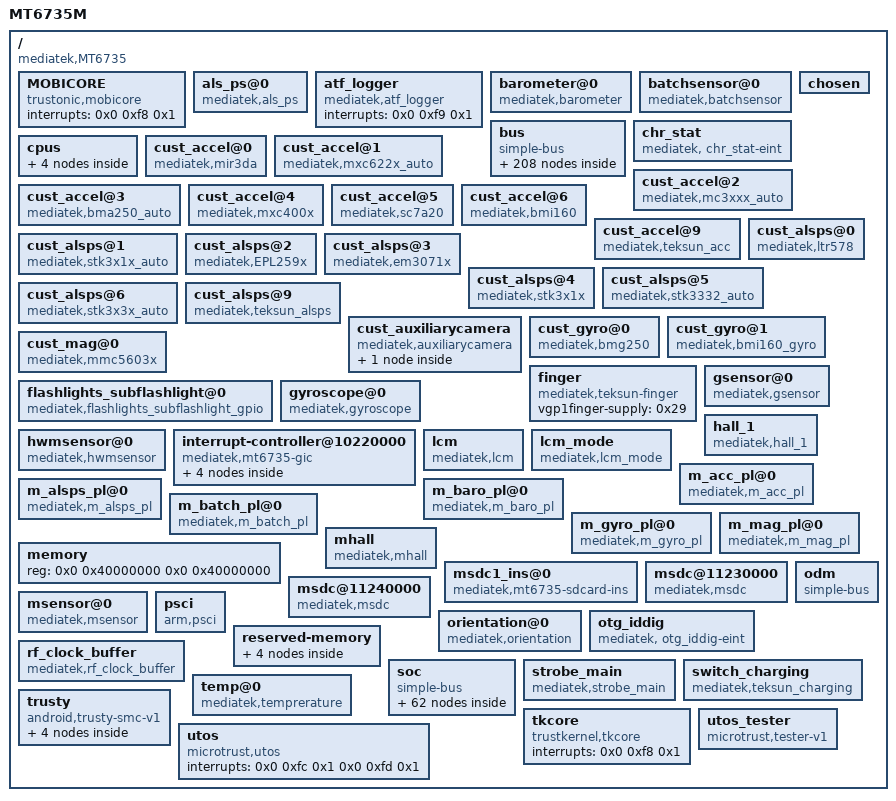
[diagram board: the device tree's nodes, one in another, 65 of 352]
/dts-v1/;

/ {
	#address-cells = <0x2>;
	#size-cells = <0x2>;
	compatible = "mediatek,MT6735";
	interrupt-parent = <0x1>;
	model = "MT6735M";

	MOBICORE {
		compatible = "trustonic,mobicore";
		interrupts = <0x0 0xf8 0x1>;
	};

	__symbols__ {
		RFIC0_01_mode = "/bus/pinctrl@0x10211000/clockbuf@1";
		RFIC0_04_mode = "/bus/pinctrl@0x10211000/clockbuf@2";
		accdet = "/bus/accdet@";
		accel = "/gsensor@0";
		als = "/soc/als";
		alsps = "/als_ps@0";
		ap_dma = "/bus/dma@11000000";
		apirtx = "/soc/irtx@11011000";
		apuart0 = "/soc/apuart0@11002000";
		apuart1 = "/soc/apuart1@11003000";
		apuart2 = "/soc/apuart2@11004000";
		apuart3 = "/soc/apuart3@11005000";
		apxgpt = "/soc/apxgpt@10004000";
		audgpio = "/bus/mt_soc_dl1_pcm@11220000";
		auxadc = "/bus/adc_hw@11001000";
		auxiliarycamera_parameter = "/cust_auxiliarycamera/auxiliarycamera_parameter";
		bat_comm = "/bus/bat_comm";
		bat_meter = "/bus/bat_meter";
		bat_notify = "/bus/bat_notify";
		bus = "/bus";
		chosen = "/chosen";
		chr_stat = "/chr_stat";
		consys = "/soc/consys@18070000";
		cpu0 = "/cpus/cpu@000";
		cpu1 = "/cpus/cpu@001";
		cpu2 = "/cpus/cpu@002";
		cpu3 = "/cpus/cpu@003";
		cpu_dbgapb = "/bus/cpu_dbgapb";
		cpus = "/cpus";
		cpuxgpt = "/soc/cpuxgpt@10200000";
		cust_accel_bma250_auto = "/cust_accel@3";
		cust_accel_bmi160 = "/cust_accel@6";
		cust_accel_mc3xxx_auto = "/cust_accel@2";
		cust_accel_mir3da = "/cust_accel@0";
		cust_accel_mxc4005xc = "/cust_accel@4";
		cust_accel_mxc622x_auto = "/cust_accel@1";
		cust_accel_sc7a20 = "/cust_accel@5";
		cust_alsps = "/cust_alsps@9";
		cust_alsps_em3071x = "/cust_alsps@3";
		cust_alsps_epl259x = "/cust_alsps@2";
		cust_alsps_ltr559 = "/cust_alsps@0";
		cust_alsps_ltr578 = "/cust_alsps@0";
		cust_alsps_stk3332_auto = "/cust_alsps@5";
		cust_alsps_stk3x1x = "/cust_alsps@4";
		cust_alsps_stk3x1x_auto = "/cust_alsps@1";
		cust_alsps_stk3x3x_auto = "/cust_alsps@6";
		cust_auxiliarycamera = "/cust_auxiliarycamera";
		cust_gyro_bmg250 = "/cust_gyro@0";
		cust_gyro_bmi160 = "/cust_gyro@1";
		cust_mag_bmm150_new = "/cust_mag@0";
		cust_mag_mmc5603x = "/cust_mag@0";
		ddrphy = "/soc/ddrphy@10213000";
		dramc = "/soc/dramc@10214000";
		dramc_nao = "/soc/dramc_nao@1020e000";
		dsi_te = "/soc/dsi_te";
		eintc = "/bus/eintc@10005000";
		ext_buck_oc = "/soc/ext_buck_oc";
		finger = "/finger";
		flashlight = "/strobe_main";
		flashlight_core = "/bus/flashlight_core";
		flashlights_lm3642 = "/bus/flashlights_lm3642";
		gic = "/interrupt-controller@10220000";
		gpio = "/soc/gpio@10211000";
		gpio_usage_mapping = "/soc/gpio";
		gse_1 = "/soc/gse_1";
		gyro = "/gyroscope@0";
		hacc = "/soc/hacc@10008000";
		hall_1 = "/hall_1";
		hwrng = "/soc/hwrng";
		i2c0 = "/bus/i2c@11007000";
		i2c1 = "/bus/i2c@11008000";
		i2c2 = "/bus/i2c@11009000";
		i2c3 = "/bus/i2c@1100f000";
		kd_camera_hw1 = "/bus/kd_camera_hw1@15008000";
		kd_camera_hw2 = "/bus/kd_camera_hw2@15008000";
		keypad = "/bus/keypad@10003000";
		lcm = "/lcm";
		lcm_mode = "/lcm_mode";
		lcm_rst = "/bus/pinctrl@0x10211000/lcm_rst_gpio_mode1@gpio146";
		lcm_rst_default = "/bus/pinctrl@0x10211000/lcmrstdefault";
		lcm_rst_gpio_high = "/bus/pinctrl@0x10211000/lcm_rst_gpio_mode2@gpio146";
		lcm_rst_gpio_low = "/bus/pinctrl@0x10211000/lcm_rst_gpio_mode3@gpio146";
		mcu_biu = "/soc/mcu_biu@10300000";
		mcucfg = "/bus/mcucfg@10200000";
		mdcldma = "/bus/mdcldma@1000A000";
		met_smi = "/bus/met_smi@14017000";
		mhall = "/mhall";
		mmsys_config = "/bus/mmsys_config@14000000";
		msdc0 = "/msdc@11230000";
		msdc1 = "/msdc@11240000";
		msdc1_ins = "/msdc1_ins@0";
		mt_pmic_vaud28_ldo_reg = "/soc/mt_pmic_regulator/ldo_regulators/ldo_vaud28";
		mt_pmic_vaux18_ldo_reg = "/soc/mt_pmic_regulator/ldo_regulators/ldo_vaux18";
		mt_pmic_vcam_af_ldo_reg = "/soc/mt_pmic_regulator/ldo_regulators/ldo_vcamaf";
		mt_pmic_vcam_io_ldo_reg = "/soc/mt_pmic_regulator/ldo_regulators/ldo_vcamio";
		mt_pmic_vcama_ldo_reg = "/soc/mt_pmic_regulator/ldo_regulators/ldo_vcama";
		mt_pmic_vcamd_ldo_reg = "/soc/mt_pmic_regulator/ldo_regulators/ldo_vcamd";
		mt_pmic_vcn18_ldo_reg = "/soc/mt_pmic_regulator/ldo_regulators/ldo_vcn18";
		mt_pmic_vcn28_ldo_reg = "/soc/mt_pmic_regulator/ldo_regulators/ldo_vcn28";
		mt_pmic_vcn33_bt_ldo_reg = "/soc/mt_pmic_regulator/ldo_regulators/ldo_vcn33_bt";
		mt_pmic_vcn33_wifi_ldo_reg = "/soc/mt_pmic_regulator/ldo_regulators/ldo_vcn33_wifi";
		mt_pmic_vcore1_buck_reg = "/soc/mt_pmic_regulator/buck_regulators/buck_vcore1";
		mt_pmic_vefuse_ldo_reg = "/soc/mt_pmic_regulator/ldo_regulators/ldo_vefuse";
		mt_pmic_vemc33_ldo_reg = "/soc/mt_pmic_regulator/ldo_regulators/ldo_vemc_3v3";
		mt_pmic_vgp1_ldo_reg = "/soc/mt_pmic_regulator/ldo_regulators/ldo_vgp1";
		mt_pmic_vibr_ldo_reg = "/soc/mt_pmic_regulator/ldo_regulators/ldo_vibr";
		mt_pmic_vio18_ldo_reg = "/soc/mt_pmic_regulator/ldo_regulators/ldo_vio18";
		mt_pmic_vio28_ldo_reg = "/soc/mt_pmic_regulator/ldo_regulators/ldo_vio28";
		mt_pmic_vlte_buck_reg = "/soc/mt_pmic_regulator/buck_regulators/buck_vlte";
		mt_pmic_vm_ldo_reg = "/soc/mt_pmic_regulator/ldo_regulators/ldo_vm";
		mt_pmic_vmc_ldo_reg = "/soc/mt_pmic_regulator/ldo_regulators/ldo_vmc";
		mt_pmic_vmch_ldo_reg = "/soc/mt_pmic_regulator/ldo_regulators/ldo_vmch";
		mt_pmic_vpa_buck_reg = "/soc/mt_pmic_regulator/buck_regulators/buck_vpa";
		mt_pmic_vproc_buck_reg = "/soc/mt_pmic_regulator/buck_regulators/buck_vproc";
		mt_pmic_vrf18_0_ldo_reg = "/soc/mt_pmic_regulator/ldo_regulators/ldo_vrf18_0";
		mt_pmic_vrf18_1_ldo_reg = "/soc/mt_pmic_regulator/ldo_regulators/ldo_vrf18_1";
		mt_pmic_vsim1_ldo_reg = "/soc/mt_pmic_regulator/ldo_regulators/ldo_vsim1";
		mt_pmic_vsim2_ldo_reg = "/soc/mt_pmic_regulator/ldo_regulators/ldo_vsim2";
		mt_pmic_vsram_ldo_reg = "/soc/mt_pmic_regulator/ldo_regulators/ldo_vsram";
		mt_pmic_vsys22_buck_reg = "/soc/mt_pmic_regulator/buck_regulators/buck_vsys22";
		mt_pmic_vtcxo_0_ldo_reg = "/soc/mt_pmic_regulator/ldo_regulators/ldo_vtcxo_0";
		mt_pmic_vtcxo_1_ldo_reg = "/soc/mt_pmic_regulator/ldo_regulators/ldo_vtcxo_1";
		mt_pmic_vtref_ldo_reg = "/soc/mt_pmic_regulator/ldo_regulators/ldo_vtref";
		mt_pmic_vusb33_ldo_reg = "/soc/mt_pmic_regulator/ldo_regulators/ldo_vusb33";
		nfc = "/bus/nfc@0";
		odm = "/odm";
		otg_iddig = "/otg_iddig";
		pio = "/bus/pinctrl@0x10211000";
		pwm = "/bus/pwm@11006000";
		reserved_memory = "/reserved-memory";
		rf_clock_buffer_ctrl = "/rf_clock_buffer";
		spi0 = "/soc/spi@1100a000";
		ssw = "/bus/simswitch@0";
		ssw_default = "/bus/pinctrl@0x10211000/ssw0default";
		ssw_hot_plug_mode1 = "/bus/pinctrl@0x10211000/ssw@1";
		ssw_hot_plug_mode2 = "/bus/pinctrl@0x10211000/ssw@2";
		ssw_sim1_md3_sim2_md1 = "/bus/pinctrl@0x10211000/ssw@4";
		ssw_two_sims_bound_to_md1 = "/bus/pinctrl@0x10211000/ssw@3";
		subflashlight = "/flashlights_subflashlight@0";
		switch_charging = "/switch_charging";
		swtp = "/soc/swtp";
		sys_cirq = "/bus/sys_cirq@10204000";
		syscfg_pctl_a = "/bus/syscfg_pctl_a@0x10211000";
		temp = "/temp@0";
		toprgu = "/soc/toprgu@10212000";
		touch = "/bus/touch@";
		usb0 = "/bus/usb20@11200000";
		usb2jtag = "/bus/usb2jtag@10000000";
		usbiddig = "/bus/usbiddig";
		vsram_default = "/bus/pinctrl@0x10211000/vsram0default";
		vsram_output_high = "/bus/pinctrl@0x10211000/vsram@2";
		vsram_output_low = "/bus/pinctrl@0x10211000/vsram@1";
	};

	als_ps@0 {
		compatible = "mediatek,als_ps";
		linux,phandle = <0x75>;
		phandle = <0x75>;
	};

	atf_logger {
		compatible = "mediatek,atf_logger";
		interrupts = <0x0 0xf9 0x1>;
	};

	barometer@0 {
		compatible = "mediatek,barometer";
	};

	batchsensor@0 {
		compatible = "mediatek,batchsensor";
	};

	bus {
		#address-cells = <0x1>;
		#size-cells = <0x1>;
		compatible = "simple-bus";
		linux,phandle = <0x55>;
		phandle = <0x55>;
		ranges = <0x0 0x0 0x0 0xffffffff>;

		APMIXED@0x10209000 {
			compatible = "mediatek,APMIXED";
			reg = <0x10209000 0x1000>;
		};

		AP_CCIF1@0x10218000 {
			compatible = "mediatek,AP_CCIF1";
			interrupts = <0x0 0x8b 0x4>;
			reg = <0x10218000 0x1000>;
		};

		AP_DMA_IRDA@0x11000100 {
			compatible = "mediatek,AP_DMA_IRDA";
			interrupts = <0x0 0x62 0x8>;
			reg = <0x11000100 0x80>;
		};

		C2KPERIPHERALS@0x38000000 {
			compatible = "mediatek,C2K PERIPHERALS";
			reg = <0x38000000 0x0>;
		};

		CA9@0x10220000 {
			compatible = "mediatek,CA9";
			reg = <0x10220000 0x8000>;
		};

		CAM@0x15004000 {
			compatible = "mediatek,CAM";
			interrupts = <0x0 0xb7 0x8>;
			reg = <0x15004000 0x1000>;
		};

		CHIPID@08000000 {
			compatible = "mediatek,CHIPID";
			reg = <0x8000000 0x4 0x8000004 0x4 0x8000008 0x4 0x800000c 0x4>;
		};

		CKSYS@0x10210000 {
			compatible = "mediatek,CKSYS";
			reg = <0x10210000 0x1000>;
		};

		DBGAPB@0x10400000 {
			compatible = "mediatek,DBGAPB";
			interrupts = <0x0 0x84 0x8>;
			reg = <0x10400000 0xc00000>;
		};

		DEBUGTOP_CA7L@0x10800000 {
			compatible = "mediatek,DEBUGTOP_CA7L";
			reg = <0x10800000 0x400000>;
		};

		DEBUGTOP_MD1@0x10450000 {
			compatible = "mediatek,DEBUGTOP_MD1";
			reg = <0x10450000 0x20000>;
		};

		DEBUGTOP_MD2@0x10470000 {
			compatible = "mediatek,DEBUGTOP_MD2";
			reg = <0x10470000 0x10000>;
		};

		DEVAPC@10207000 {
			compatible = "mediatek,DEVAPC";
			interrupts = <0x0 0x86 0x8>;
			reg = <0x10207000 0x1000>;
		};

		DEVAPC_AO@10007000 {
			compatible = "mediatek,DEVAPC_AO";
			reg = <0x10007000 0x1000>;
		};

		DISPSYS@14007000 {
			compatible = "mediatek,DISPSYS";
			interrupts = <0x0 0xc1 0x8 0x0 0x0 0x8 0x0 0xc3 0x8 0x0 0x0 0x8 0x0 0xc5 0x8 0x0 0xc6 0x8 0x0 0xc7 0x8 0x0 0xc8 0x8 0x0 0xc9 0x8 0x0 0xca 0x8 0x0 0x0 0x8 0x0 0x75 0x8 0x0 0x0 0x8 0x0 0xba 0x8 0x0 0xcc 0x8 0x0 0xcd 0x8 0x0 0xce 0x8 0x0 0xb0 0x8 0x0 0x0 0x8 0x0 0x0 0x8 0x0 0x0 0x8 0x0 0x0 0x8 0x0 0x0 0x8 0x0 0x0 0x8 0x0 0x0 0x8 0x0 0x0 0x8 0x0 0x0 0x8 0x0 0x0 0x8>;
			reg = <0x14007000 0x1000 0x0 0x0 0x14009000 0x1000 0x0 0x0 0x1400b000 0x1000 0x1400c000 0x1000 0x1400d000 0x1000 0x1400e000 0x1000 0x1400f000 0x1000 0x14010000 0x1000 0x0 0x0 0x1100e000 0x1000 0x0 0x0 0x14015000 0x1000 0x14012000 0x1000 0x14013000 0x1000 0x14000000 0x1000 0x14016000 0x1000 0x14017000 0x1000 0x14018000 0x1000 0x10206000 0x1000 0x10210000 0x1000 0x10211a70 0xc 0x10211974 0xc 0x10211b70 0xc 0x10206044 0xc 0x10206514 0xc 0x10206558 0xc 0x102100a0 0x1000 0x10209260 0x1000 0x10209264 0x1000 0x0 0x0 0x10209000 0x1000>;
		};

		DISP_AAL@0x1400E000 {
			compatible = "mediatek,DISP_AAL";
			interrupts = <0x0 0xc8 0x8>;
			reg = <0x1400e000 0x1000>;
		};

		DISP_CCORR@0x1400D000 {
			compatible = "mediatek,DISP_CCORR";
			interrupts = <0x0 0xc7 0x8>;
			reg = <0x1400d000 0x1000>;
		};

		DISP_COLOR@0x1400C000 {
			compatible = "mediatek,DISP_COLOR";
			interrupts = <0x0 0xc6 0x8>;
			reg = <0x1400c000 0x1000>;
		};

		DISP_DITHER@0x14010000 {
			compatible = "mediatek,DISP_DITHER";
			interrupts = <0x0 0xca 0x8>;
			reg = <0x14010000 0x1000>;
		};

		DISP_GAMMA@0x1400F000 {
			compatible = "mediatek,DISP_GAMMA";
			interrupts = <0x0 0xc9 0x8>;
			reg = <0x1400f000 0x1000>;
		};

		DISP_OVL0@0x14007000 {
			compatible = "mediatek,DISP_OVL0";
			interrupts = <0x0 0xc1 0x8>;
			reg = <0x14007000 0x1000>;
		};

		DISP_OVL1@0x14008000 {
			compatible = "mediatek,DISP_OVL1";
			interrupts = <0x0 0xc2 0x8>;
			reg = <0x14008000 0x1000>;
		};

		DISP_PWM0@0x1100E000 {
			compatible = "mediatek,DISP_PWM0";
			reg = <0x1100e000 0x1000>;
		};

		DISP_PWM@0x14014000 {
			compatible = "mediatek,DISP_PWM";
			reg = <0x14014000 0x1000>;
		};

		DISP_RDMA0@0x14009000 {
			compatible = "mediatek,DISP_RDMA0";
			interrupts = <0x0 0xc3 0x8>;
			reg = <0x14009000 0x1000>;
		};

		DISP_RDMA1@0x1400A000 {
			compatible = "mediatek,DISP_RDMA1";
			interrupts = <0x0 0xc4 0x8>;
			reg = <0x1400a000 0x1000>;
		};

		DISP_UFOE@0x14011000 {
			compatible = "mediatek,DISP_UFOE";
			interrupts = <0x0 0xcb 0x8>;
			reg = <0x14011000 0x1000>;
		};

		DISP_WDMA0@0x1400B000 {
			compatible = "mediatek,DISP_WDMA0";
			interrupts = <0x0 0xc5 0x8>;
			reg = <0x1400b000 0x1000>;
		};

		DNL3_XGPT64@0x1000C000 {
			compatible = "mediatek,DNL3_XGPT64";
			interrupts = <0x0 0x9f 0x8>;
			reg = <0x1000c000 0x1000>;
		};

		DPI0@0x14013000 {
			compatible = "mediatek,DPI0";
			interrupts = <0x0 0xcd 0x8>;
			reg = <0x14013000 0x1000>;
		};

		DSI0@0x14012000 {
			compatible = "mediatek,DSI0";
			interrupts = <0x0 0xcc 0x8>;
			reg = <0x14012000 0x1000>;
		};

		EFUSEC@10206000 {
			compatible = "mediatek,EFUSEC";
			reg = <0x10206000 0x1000>;
		};

		EMI@0x10203000 {
			compatible = "mediatek,EMI";
			interrupts = <0x0 0x88 0x4>;
			reg = <0x10203000 0x1000>;
		};

		FHCTL@0x10209F00 {
			compatible = "mediatek,FHCTL";
			reg = <0x10209f00 0x100>;
		};

		G3D_CONFIG@0x13000000 {
			compatible = "mediatek,G3D_CONFIG";
			reg = <0x13000000 0x1000>;
		};

		IMGSYS@0x15000000 {
			compatible = "mediatek,IMGSYS";
			reg = <0x15000000 0x1000>;
		};

		INFRACFG@0x10201000 {
			compatible = "mediatek,INFRACFG";
			reg = <0x10201000 0x1000>;
		};

		INFRACFG_AO@0x10000000 {
			compatible = "mediatek,INFRACFG_AO";
			reg = <0x10000000 0x1000>;
		};

		INFRA_MBIST@0x1020D000 {
			compatible = "mediatek,INFRA_MBIST";
			reg = <0x1020d000 0x1000>;
		};

		INFRA_MD@0x1021C000 {
			compatible = "mediatek,INFRA_MD";
			reg = <0x1021c000 0x1000>;
		};

		IRDA@0x11010000 {
			compatible = "mediatek,IRDA";
			reg = <0x11010000 0x1000>;
		};

		ISPSYS@0x15000000 {
			compatible = "mediatek,ISPSYS";
			interrupts = <0x0 0xb6 0x8 0x0 0xb7 0x8>;
			reg = <0x15004000 0x9000 0x15000000 0x10000 0x10215000 0x1000>;
		};

		ISP_PIPEM@0x15000000 {
			compatible = "mediatek,ISP_PIPEM";
		};

		ISP_SYSR@0x15000000 {
			compatible = "mediatek,ISP_SYSR";
		};

		JPGENC@0x1500A000 {
			compatible = "mediatek,JPGENC";
			interrupts = <0x0 0xb5 0x8>;
			reg = <0x1500a000 0x1000>;
		};

		MALI@0x13040000 {
			clock-frequency = <0x1ad27480>;
			compatible = "arm,malit720", "arm,mali-t72x", "arm,malit7xx", "arm,mali-midgard";
			interrupt-names = "JOB", "MMU", "GPU";
			interrupts = <0x0 0xd4 0x8 0x0 0xd3 0x8 0x0 0xd2 0x8>;
			reg = <0x13040000 0x4000>;
		};

		MCUCFG@0x10200000 {
			compatible = "mediatek,MCUCFG";
			interrupts = <0x0 0x0 0x8>;
			reg = <0x10200000 0x200>;
		};

		MCUSYS_MCUCFG@0x10200600 {
			compatible = "mediatek,MCUSYS_MCUCFG";
			reg = <0x10200600 0xa00>;
		};

		MCUSYS_MISCCFG@0x10200400 {
			compatible = "mediatek,MCUSYS_MISCCFG";
			reg = <0x10200400 0x200>;
		};

		MD2PERIPHERALS@0x30000000 {
			compatible = "mediatek,MD2 PERIPHERALS";
			reg = <0x30000000 0x0>;
		};

		MDPERIPHERALS@0x20000000 {
			compatible = "mediatek,MD PERIPHERALS";
			reg = <0x20000000 0x0>;
		};

		MD_CCIF1@0x10219000 {
			compatible = "mediatek,MD_CCIF1";
			reg = <0x10219000 0x1000>;
		};

		MFGCFG@0x13000000 {
			compatible = "mediatek,MFGCFG";
			interrupts = <0x0 0xd2 0x8>;
			reg = <0x13000000 0x1000>;
		};

		MIPI_RX_ANA_CSI0@0x10215800 {
			compatible = "mediatek,MIPI_RX_ANA_CSI0";
			reg = <0x10215800 0x400>;
		};

		MIPI_RX_ANA_CSI1@0x10215C00 {
			compatible = "mediatek,MIPI_RX_ANA_CSI1";
			reg = <0x10215c00 0x400>;
		};

		MIPI_TX_CONFIG@0x14018000 {
			compatible = "mediatek,MIPI_TX_CONFIG";
			reg = <0x14018000 0x1000>;
		};

		MM_MUTEX@0x14015000 {
			compatible = "mediatek,MM_MUTEX";
			interrupts = <0x0 0xba 0x8>;
			reg = <0x14015000 0x1000>;
		};

		NFI@0x1100D000 {
			compatible = "mediatek,NFI";
			interrupts = <0x0 0x60 0x8>;
			reg = <0x1100d000 0x1000>;
		};

		PERICFG@0x10002000 {
			compatible = "mediatek,PERICFG";
			reg = <0x10002000 0x1000>;
		};

		PWM@0x11006000 {
			compatible = "mediatek,pwm";
			interrupts = <0x0 0x4d 0x8>;
			reg = <0x11006000 0x1000>;
		};

		PWRAP@0x10001000 {
			compatible = "mediatek,PWRAP";
			interrupts = <0x0 0xa3 0x4>;
			reg = <0x10001000 0x1000>;
		};

		RSVD@0x10009000 {
			compatible = "mediatek,RSVD";
			reg = <0x10009000 0x1000>;
		};

		RSVD@0x10200200 {
			compatible = "mediatek,RSVD";
			reg = <0x10200200 0x200>;
		};

		RSVD@0x1020C000 {
			compatible = "mediatek,RSVD";
			reg = <0x1020c000 0x1000>;
		};

		SENINF_TOP@0x15008000 {
			compatible = "mediatek,SENINF_TOP";
			interrupts = <0x0 0xb6 0x8>;
			reg = <0x15008000 0x1000>;
		};

		SLEEP@0x10006000 {
			compatible = "mediatek,SLEEP";
			interrupts = <0x0 0xa5 0x8 0x0 0xa6 0x8 0x0 0xa7 0x8 0x0 0xa8 0x8>;
			reg = <0x10006000 0x1000>;
		};

		SPI1@0x1100A000 {
			cell-index = <0x0>;
			compatible = "mediatek,SPI1";
			interrupts = <0x0 0x76 0x8>;
			reg = <0x1100a000 0x1000>;
			spi-padmacro = <0x0>;
		};

		SRAMROM@0x10202000 {
			compatible = "mediatek,SRAMROM";
			reg = <0x10202000 0x1000>;
		};

		THERM_CTRL@0x1100B000 {
			compatible = "mediatek,THERM_CTRL";
			interrupts = <0x0 0x4e 0x8>;
			reg = <0x1100b000 0x1000>;
		};

		TRNG@0x1020F000 {
			compatible = "mediatek,TRNG";
			interrupts = <0x0 0x8d 0x8>;
			reg = <0x1020f000 0x1000>;
		};

		USB1@0x11260000 {
			compatible = "mediatek,USB1";
			interrupts = <0x0 0x49 0x8>;
			reg = <0x11260000 0x10000>;
		};

		VDEC@0x1500B000 {
			compatible = "mediatek,VDEC";
			reg = <0x1500b000 0x1000>;
		};

		VDEC_FULL_TOP@0x16020000 {
			compatible = "mediatek,VDEC_FULL_TOP";
			interrupts = <0x0 0xb3 0x8>;
			reg = <0x16020000 0x10000>;
		};

		VDEC_GCON@0x16000000 {
			compatible = "mediatek,VDEC_GCON";
			reg = <0x16000000 0x1000>;
		};

		VENC@0x15009000 {
			compatible = "mediatek,VENC";
			interrupts = <0x0 0xb4 0x8>;
			reg = <0x15009000 0x1000>;
		};

		WCN_AHB@0x11270000 {
			compatible = "mediatek,WCN_AHB";
			interrupts = <0x0 0xe4 0x8>;
			reg = <0x11270000 0x10000>;
		};

		accdet@ {
			compatible = "mediatek,pmic-accdet";
			linux,phandle = <0x68>;
			phandle = <0x68>;
		};

		adc_hw@11001000 {
			compatible = "mediatek,mt6735-auxadc";
			interrupts = <0x0 0x4c 0x2>;
			linux,phandle = <0x61>;
			phandle = <0x61>;
			reg = <0x11001000 0x1000>;
		};

		audio@11220000 {
			compatible = "mediatek,audio";
			interrupts = <0x0 0x90 0x8>;
			reg = <0x11220000 0x10000>;
		};

		bat_comm {
			compatible = "mediatek,battery";
			linux,phandle = <0x5a>;
			phandle = <0x5a>;
		};

		bat_meter {
			compatible = "mediatek,bat_meter";
			linux,phandle = <0x58>;
			phandle = <0x58>;
		};

		bat_notify {
			compatible = "mediatek,bat_notify";
			linux,phandle = <0x59>;
			phandle = <0x59>;
		};

		btcvsd@10000000 {
			compatible = "mediatek,audio_bt_cvsd";
			interrupts = <0x0 0xe4 0x8>;
			offset = <0x700 0x800 0xfd0 0xfd4 0xfd8>;
			reg = <0x10000000 0x1000 0x18000000 0x10000 0x18080000 0x8000>;
		};

		btif@0x1100C000 {
			#address-cells = <0x2>;
			#size-cells = <0x2>;
			compatible = "mediatek,btif";
			interrupts = <0x0 0x5a 0x8 0x0 0x6f 0x8 0x0 0x70 0x8>;
			reg = <0x1100c000 0x1000 0x11000780 0x80 0x11000800 0x80>;
		};

		bus_dbg@10208000 {
			compatible = "mediatek,bus_dbg-v1";
			interrupts = <0x0 0x89 0x8>;
			reg = <0x10208000 0x1000>;
		};

		cpu_dbgapb {
			compatible = "mediatek,hw_dbg";
			linux,phandle = <0x5f>;
			num = <0x4>;
			phandle = <0x5f>;
			reg = <0x10810000 0x1000 0x10910000 0x1000 0x10a10000 0x1000 0x10b10000 0x1000>;
		};

		cqdma@10217c00 {
			compatible = "mediatek,cqdma";
			interrupts = <0x0 0x8a 0x8>;
			nr_channel = <0x1>;
			reg = <0x10217c00 0x400>;
		};

		dbgapb_base@1011A000 {
			compatible = "mediatek,dbgapb_base";
			reg = <0x1011a000 0x100>;
		};

		dma@11000000 {
			compatible = "mediatek,ap_dma";
			interrupts = <0x0 0x61 0x8>;
			linux,phandle = <0x60>;
			phandle = <0x60>;
			reg = <0x11000000 0x1000>;
		};

		eintc@10005000 {
			#interrupt-cells = <0x2>;
			compatible = "mediatek,mt-eic";
			interrupt-controller;
			interrupts = <0x0 0x99 0x4>;
			linux,phandle = <0x1c>;
			mediatek,debtime_setting_array = <0x0 0x7d 0x1 0xfa 0x2 0x1f4 0x3 0x3e8 0x4 0x3e80 0x5 0x7d00 0x6 0xfa00 0x7 0x1f400 0x8 0x3e800 0x9 0x7d000>;
			mediatek,debtime_setting_entry = <0xa>;
			mediatek,mapping_table_entry = <0x0>;
			mediatek,max_eint_num = <0xd5>;
			phandle = <0x1c>;
			reg = <0x10005000 0x1000>;

			pmic@206 {
				compatible = "mediatek, pmic-eint";
				debounce = <0xce 0x3e8>;
				interrupt-parent = <0x1c>;
				interrupts = <0xce 0x4>;
			};
		};

		flashlight_core {
			compatible = "mediatek,flashlight_core";
			linux,phandle = <0x70>;
			phandle = <0x70>;
		};

		flashlights_lm3642 {
			compatible = "mediatek,flashlights_lm3642";
			decouple = <0x1>;
			linux,phandle = <0x71>;
			phandle = <0x71>;

			channel@1 {
				ct = <0x0>;
				part = <0x0>;
				type = <0x0>;
			};
		};

		gce@10217000 {
			apxgpt2_count = <0x10004028>;
			audio_base = <0x11220000 0x12 0xffff0000>;
			buf_underrun_event_0 = <0x30>;
			buf_underrun_event_1 = <0x31>;
			compatible = "mediatek,gce";
			conn_peri_base = <0x18000000 0x7 0xffff0000>;
			disp_aal_frame_done = <0x20>;
			disp_aal_sof = <0xd>;
			disp_ccorr_frame_done = <0x1e>;
			disp_ccorr_sof = <0xb>;
			disp_color_frame_done = <0x1f>;
			disp_color_sof = <0xc>;
			disp_dither_base = <0x14010000 0x2 0xffff0000>;
			disp_dither_frame_done = <0x22>;
			disp_dither_sof = <0xf>;
			disp_dpi0_frame_done = <0x24>;
			disp_dsi0_frame_done = <0x25>;
			disp_gamma_frame_done = <0x21>;
			disp_gamma_sof = <0xe>;
			disp_mutex_reg = <0x14015000 0x1000>;
			disp_ovl0_frame_done = <0x19>;
			disp_ovl0_sof = <0x6>;
			disp_pwm0_sof = <0x11>;
			disp_rdma0_frame_done = <0x1b>;
			disp_rdma0_sof = <0x8>;
			disp_rdma1_frame_done = <0x1c>;
			disp_rdma1_sof = <0x9>;
			disp_wdma0_frame_done = <0x1d>;
			disp_wdma0_sof = <0xa>;
			dsi0_te_event = <0x32>;
			g3d_config_base = <0x13000000 0x0 0xffff0000>;
			gcpu_base = <0x10210000 0xf 0xffff0000>;
			imgsys_base = <0x15000000 0x4 0xffff0000>;
			infra_na3_base = <0x10030000 0xb 0xffff0000>;
			infra_na4_base = <0x10040000 0xc 0xffff0000>;
			interrupts = <0x0 0x97 0x8 0x0 0x94 0x8>;
			isp_frame_done_p2_0 = <0x43>;
			isp_frame_done_p2_1 = <0x42>;
			kp_base = <0x10010000 0x9 0xffff0000>;
			mcucfg_base = <0x10200000 0xe 0xffff0000>;
			mdp_rdma0_frame_done = <0x12>;
			mdp_rdma0_sof = <0x0>;
			mdp_rsz0_frame_done = <0x13>;
			mdp_rsz0_sof = <0x1>;
			mdp_rsz1_frame_done = <0x14>;
			mdp_rsz1_sof = <0x2>;
			mdp_tdshp_frame_done = <0x15>;
			mdp_tdshp_sof = <0x3>;
			mdp_wdma_frame_done = <0x16>;
			mdp_wdma_sof = <0x4>;
			mdp_wrot_read_frame_done = <0x18>;
			mdp_wrot_sof = <0x5>;
			mdp_wrot_write_frame_done = <0x17>;
			mm_na_base = <0x14020000 0x3 0xffff0000>;
			mmsys_config_base = <0x14000000 0x1 0xffff0000>;
			msdc0_base = <0x11230000 0x13 0xffff0000>;
			msdc1_base = <0x11240000 0x14 0xffff0000>;
			msdc2_base = <0x11250000 0x15 0xffff0000>;
			msdc3_base = <0x11260000 0x16 0xffff0000>;
			pwm_sw_base = <0x1100e000 0x63 0xfffff000>;
			reg = <0x10217000 0xc00>;
			scp_base = <0x10050000 0xd 0xffff0000>;
			scp_sram_base = <0x10020000 0xa 0xffff0000>;
			seninf_cam0_fifo_full = <0x49>;
			stream_done_0 = <0x26>;
			stream_done_1 = <0x27>;
			stream_done_2 = <0x28>;
			stream_done_3 = <0x29>;
			stream_done_4 = <0x2a>;
			stream_done_5 = <0x2b>;
			stream_done_6 = <0x2c>;
			stream_done_7 = <0x2d>;
			stream_done_8 = <0x2e>;
			stream_done_9 = <0x2f>;
			topckgen_base = <0x10000000 0x8 0xffff0000>;
			usb0_base = <0x11200000 0x10 0xffff0000>;
			usb_sif_base = <0x11210000 0x11 0xffff0000>;
			vdec_gcon_base = <0x16000000 0x5 0xffff0000>;
			venc_gcon_base = <0x17000000 0x6 0xffff0000>;
		};

		gcpu@10216000 {
			compatible = "mediatek,gcpu";
			interrupts = <0x0 0x96 0x8>;
			reg = <0x10216000 0x1000>;
		};

		gpio@0x10000e00 {
			compatible = "mediatek,fpga_gpio";
			reg = <0x10000e00 0x100>;
		};

		gps {
			compatible = "mediatek,gps";
		};

		i2c@11007000 {
			cell-index = <0x0>;
			compatible = "mediatek,mt6735m-i2c";
			def_speed = <0x64>;
			interrupts = <0x0 0x54 0x8 0x0 0x63 0x8>;
			linux,phandle = <0x63>;
			phandle = <0x63>;
			reg = <0x11007000 0x1000>;
		};

		i2c@11008000 {
			cell-index = <0x1>;
			compatible = "mediatek,mt6735m-i2c";
			def_speed = <0x64>;
			interrupts = <0x0 0x55 0x8 0x0 0x64 0x8>;
			linux,phandle = <0x64>;
			phandle = <0x64>;
			reg = <0x11008000 0x1000>;
		};

		i2c@11009000 {
			cell-index = <0x2>;
			compatible = "mediatek,mt6735m-i2c";
			def_speed = <0x64>;
			interrupts = <0x0 0x56 0x8 0x0 0x65 0x8>;
			linux,phandle = <0x65>;
			phandle = <0x65>;
			reg = <0x11009000 0x1000>;
		};

		i2c@1100f000 {
			cell-index = <0x3>;
			compatible = "mediatek,mt6735m-i2c";
			def_speed = <0x64>;
			interrupts = <0x0 0x57 0x8 0x0 0x66 0x8>;
			linux,phandle = <0x66>;
			phandle = <0x66>;
			reg = <0x1100f000 0x1000>;
		};

		kd_camera_hw1@15008000 {
			compatible = "mediatek,camera_hw";
			linux,phandle = <0x6e>;
			phandle = <0x6e>;
			reg = <0x15008000 0x1000>;
			vcama-supply = <0x2a>;
			vcamaf-supply = <0x2c>;
			vcamd-supply = <0x2b>;
			vcamio-supply = <0x2d>;
		};

		kd_camera_hw2@15008000 {
			compatible = "mediatek,camera_hw2";
			linux,phandle = <0x6f>;
			phandle = <0x6f>;
			reg = <0x15008000 0x1000>;
		};

		keypad@10003000 {
			compatible = "mediatek,kp", "mediatek,mt6735-keypad", "mediatek,mt6735m-keypad";
			interrupts = <0x0 0xa4 0x2>;
			linux,phandle = <0x57>;
			phandle = <0x57>;
			reg = <0x10003000 0x1000>;
		};

		m4u@10205000 {
			cell-index = <0x0>;
			compatible = "mediatek,m4u";
			interrupts = <0x0 0x92 0x8>;
			reg = <0x10205000 0x1000>;
		};

		mcucfg@10200000 {
			compatible = "mediatek,mt6735-mcucfg";
			interrupts = <0x0 0x47 0x4>;
			linux,phandle = <0x5d>;
			phandle = <0x5d>;
			reg = <0x10200000 0x200>;
		};

		mdcldma@1000A000 {
			compatible = "mediatek,mdcldma";
			interrupts = <0x0 0x91 0x4 0x0 0x8c 0x8 0x0 0xdd 0x2>;
			linux,phandle = <0x5b>;
			mediatek,cldma_capability = <0x2>;
			mediatek,md_id = <0x0>;
			mediatek,md_smem_size = <0x10000>;
			phandle = <0x5b>;
			pinctrl-0 = <0x1d>;
			pinctrl-1 = <0x1e>;
			pinctrl-2 = <0x1f>;
			pinctrl-3 = <0x20>;
			pinctrl-4 = <0x21>;
			pinctrl-names = "default", "vsram_output_low", "vsram_output_high", "RFIC0_01_mode", "RFIC0_04_mode";
			reg = <0x1000a000 0x1000 0x1000b000 0x1000 0x1021a000 0x1000 0x1021b000 0x1000 0x1020a000 0x1000 0x1020b000 0x1000>;
		};

		mdp_rdma@14001000 {
			compatible = "mediatek,mdp_rdma";
			interrupts = <0x0 0xbb 0x8>;
			reg = <0x14001000 0x1000>;
		};

		mdp_rsz0@14002000 {
			compatible = "mediatek,mdp_rsz0";
			interrupts = <0x0 0xbc 0x8>;
			reg = <0x14002000 0x1000>;
		};

		mdp_rsz1@14003000 {
			compatible = "mediatek,mdp_rsz1";
			interrupts = <0x0 0xbd 0x8>;
			reg = <0x14003000 0x1000>;
		};

		mdp_tdshp@14006000 {
			compatible = "mediatek,mdp_tdshp";
			interrupts = <0x0 0xbe 0x8>;
			reg = <0x14006000 0x1000>;
		};

		mdp_wdma@14004000 {
			compatible = "mediatek,mdp_wdma";
			interrupts = <0x0 0xbf 0x8>;
			reg = <0x14004000 0x1000>;
		};

		mdp_wrot@14005000 {
			compatible = "mediatek,mdp_wrot";
			interrupts = <0x0 0xc0 0x8>;
			reg = <0x14005000 0x1000>;
		};

		met_smi@14017000 {
			compatible = "mediatek,met_smi";
			linux,phandle = <0x6d>;
			phandle = <0x6d>;
			reg = <0x14017000 0x1000 0x14016000 0x1000 0x16010000 0x1000 0x15001000 0x1000 0x17001000 0x1000>;
		};

		mmsys_config@14000000 {
			compatible = "mediatek,mmsys_config";
			interrupts = <0x0 0xce 0x8>;
			linux,phandle = <0x27>;
			phandle = <0x27>;
			reg = <0x14000000 0x1000>;
		};

		mt_soc_codec_dummy_name {
			compatible = "mediatek,mt_soc_codec_dummy";
		};

		mt_soc_codec_name {
			compatible = "mediatek,mt_soc_codec_63xx";
		};

		mt_soc_dai_name {
			compatible = "mediatek,mt_soc_dai_stub";
		};

		mt_soc_deep_buffer_dl_pcm {
			compatible = "mediatek,mt_soc_pcm_deep_buffer_dl";
		};

		mt_soc_dl1_awb_pcm {
			compatible = "mediatek,mt_soc_pcm_dl1_awb";
		};

		mt_soc_dl1_pcm@11220000 {
			audclk-gpio = <0x8f 0x0>;
			audmiso-gpio = <0x90 0x0>;
			audmosi-gpio = <0x91 0x0>;
			compatible = "mediatek,mt-soc-dl1-pcm";
			extspkamp-gpio = <0x75 0x0>;
			i2s1clk-gpio = <0x50 0x0>;
			i2s1dat-gpio = <0x4e 0x0>;
			i2s1mclk-gpio = <0x9 0x0>;
			i2s1ws-gpio = <0x4f 0x0>;
			interrupts = <0x0 0x90 0x8>;
			linux,phandle = <0x6c>;
			phandle = <0x6c>;
			reg = <0x11220000 0x1000>;
			vowclk-gpio = <0x94 0x0>;
		};

		mt_soc_dl2_pcm {
			compatible = "mediatek,mt_soc_pcm_dl2";
		};

		mt_soc_dummy_pcm {
			compatible = "mediatek,mt_soc_pcm_dummy";
		};

		mt_soc_fm_i2s_awb_pcm {
			compatible = "mediatek,mt_soc_pcm_fm_i2s_awb";
		};

		mt_soc_fm_i2s_pcm {
			compatible = "mediatek,mt_soc_pcm_fm_i2s";
		};

		mt_soc_fm_mrgtx_pcm {
			compatible = "mediatek,mt_soc_pcm_fmtx";
		};

		mt_soc_hdmi_pcm {
			compatible = "mediatek,mt_soc_pcm_hdmi";
		};

		mt_soc_hp_impedance_pcm {
			compatible = "mediatek,Mt_soc_pcm_hp_impedance";
		};

		mt_soc_i2s0_awb_pcm {
			compatible = "mediatek,mt_soc_pcm_i2s0_awb";
		};

		mt_soc_i2s0_pcm {
			compatible = "mediatek,mt_soc_pcm_dl1_i2s0";
		};

		mt_soc_i2s0dl1_pcm {
			compatible = "mediatek,mt_soc_pcm_dl1_i2s0Dl1";
		};

		mt_soc_mrgrx_awb_pcm {
			compatible = "mediatek,mt_soc_pcm_mrgrx_awb";
		};

		mt_soc_mrgrx_pcm {
			compatible = "mediatek,mt_soc_pcm_mrgrx";
		};

		mt_soc_offload_gdma {
			compatible = "mediatek,mt_soc_pcm_offload_gdma";
		};

		mt_soc_routing_dai_name {
			compatible = "mediatek,mt_soc_dai_routing";
		};

		mt_soc_routing_pcm {
			compatible = "mediatek,mt_soc_pcm_routing";
			i2s1clk-gpio = <0x7 0x6>;
			i2s1dat-gpio = <0x5 0x6>;
			i2s1mclk-gpio = <0x9 0x6>;
			i2s1ws-gpio = <0x6 0x6>;
		};

		mt_soc_tdmrx_pcm {
			compatible = "mediatek,mt_soc_tdm_capture";
		};

		mt_soc_ul1_pcm {
			compatible = "mediatek,mt_soc_pcm_capture";
		};

		mt_soc_ul2_pcm {
			compatible = "mediatek,mt_soc_pcm_capture2";
		};

		mt_soc_uldlloopback_pcm {
			compatible = "mediatek,mt_soc_pcm_uldlloopback";
		};

		mt_soc_voice_md1 {
			compatible = "mediatek,mt_soc_pcm_voice_md1";
		};

		mt_soc_voice_md1_bt {
			compatible = "mediatek,mt_soc_pcm_voice_md1_bt";
		};

		mt_soc_voice_md2 {
			compatible = "mediatek,mt_soc_pcm_voice_md2";
		};

		mt_soc_voice_md2_bt {
			compatible = "mediatek,mt_soc_pcm_voice_md2_bt";
		};

		mt_soc_voip_bt_in {
			compatible = "mediatek,mt_soc_pcm_bt_dai";
		};

		mt_soc_voip_bt_out {
			compatible = "mediatek,mt_soc_pcm_dl1_bt";
		};

		nfc@0 {
			compatible = "mediatek,nfc-gpio-v2";
			gpio-eint = <0x1>;
			gpio-irq = <0x2>;
			gpio-rst = <0x3>;
			gpio-ven = <0x4>;
			linux,phandle = <0x69>;
			phandle = <0x69>;
		};

		pinctrl@0x10211000 {
			#gpio-cells = <0x2>;
			compatible = "mediatek,mt6735-pinctrl";
			gpio-controller;
			linux,phandle = <0x62>;
			mediatek,pctl-regmap = <0x28>;
			phandle = <0x62>;
			pins-are-numbered;
			reg = <0x10211000 0x1000>;

			clockbuf@1 {
				linux,phandle = <0x20>;
				phandle = <0x20>;

				pins_cmd0_dat {
					pinmux = <0x6e01>;
				};

				pins_cmd1_dat {
					pinmux = <0x6f01>;
				};

				pins_cmd2_dat {
					pinmux = <0x7001>;
				};

				pins_cmd3_dat {
					pinmux = <0x7101>;
				};

				pins_cmd4_dat {
					pinmux = <0x7201>;
				};
			};

			clockbuf@2 {
				linux,phandle = <0x21>;
				phandle = <0x21>;

				pins_cmd0_dat {
					pinmux = <0x6e04>;
				};

				pins_cmd1_dat {
					pinmux = <0x6f04>;
				};

				pins_cmd2_dat {
					pinmux = <0x7004>;
				};

				pins_cmd3_dat {
					pinmux = <0x7104>;
				};

				pins_cmd4_dat {
					pinmux = <0x7204>;
				};
			};

			lcm_rst_gpio_mode1@gpio146 {
				linux,phandle = <0x2f>;
				phandle = <0x2f>;

				pins_cmd_dat {
					pins = <0x9201>;
				};
			};

			lcm_rst_gpio_mode2@gpio146 {
				linux,phandle = <0x30>;
				phandle = <0x30>;

				pins_cmd_dat {
					output-high;
					pins = <0x9200>;
					slew-rate = <0x1>;
				};
			};

			lcm_rst_gpio_mode3@gpio146 {
				linux,phandle = <0x31>;
				phandle = <0x31>;

				pins_cmd_dat {
					output-low;
					pins = <0x9200>;
					slew-rate = <0x1>;
				};
			};

			lcmrstdefault {
				linux,phandle = <0x2e>;
				phandle = <0x2e>;
			};

			ssw0default {
				linux,phandle = <0x22>;
				phandle = <0x22>;
			};

			ssw@1 {
				linux,phandle = <0x23>;
				phandle = <0x23>;

				pins_cmd0_dat {
					pinmux = <0x904>;
				};

				pins_cmd1_dat {
					pinmux = <0x904>;
				};
			};

			ssw@2 {
				linux,phandle = <0x24>;
				phandle = <0x24>;

				pins_cmd0_dat {
					pinmux = <0x904>;
				};

				pins_cmd1_dat {
					pinmux = <0x904>;
				};
			};

			ssw@3 {
				linux,phandle = <0x25>;
				phandle = <0x25>;

				pins_cmd0_dat {
					pinmux = <0xa301>;
					slew-rate = <0x1>;
				};

				pins_cmd1_dat {
					pinmux = <0xa401>;
					slew-rate = <0x1>;
				};

				pins_cmd2_dat {
					bias-pull-up = <0x0>;
					pinmux = <0xa501>;
					slew-rate = <0x0>;
				};

				pins_cmd3_dat {
					pinmux = <0xa001>;
					slew-rate = <0x1>;
				};

				pins_cmd4_dat {
					pinmux = <0xa101>;
					slew-rate = <0x1>;
				};

				pins_cmd5_dat {
					bias-pull-up = <0x0>;
					pinmux = <0xa201>;
					slew-rate = <0x0>;
				};
			};

			ssw@4 {
				linux,phandle = <0x26>;
				phandle = <0x26>;

				pins_cmd0_dat {
					pinmux = <0xa304>;
				};

				pins_cmd1_dat {
					pinmux = <0xa404>;
				};

				pins_cmd2_dat {
					pinmux = <0xa504>;
				};

				pins_cmd3_dat {
					pinmux = <0xa001>;
				};

				pins_cmd4_dat {
					pinmux = <0xa101>;
				};

				pins_cmd5_dat {
					pinmux = <0xa201>;
				};
			};

			vsram0default {
				linux,phandle = <0x1d>;
				phandle = <0x1d>;
			};

			vsram@1 {
				linux,phandle = <0x1e>;
				phandle = <0x1e>;

				pins_cmd_dat {
					output-low;
					pinmux = <0x8c00>;
					slew-rate = <0x1>;
				};
			};

			vsram@2 {
				linux,phandle = <0x1f>;
				phandle = <0x1f>;

				pins_cmd_dat {
					output-high;
					pinmux = <0x8c00>;
					slew-rate = <0x1>;
				};
			};
		};

		ptp_fsm@1100b000 {
			compatible = "mediatek,ptp_fsm_v1";
			interrupts = <0x0 0x7d 0x8>;
			reg = <0x1100b000 0x1000>;
		};

		pwm@11006000 {
			compatible = "mediatek,pwm";
			interrupts = <0x0 0x4d 0x8>;
			linux,phandle = <0x72>;
			phandle = <0x72>;
			reg = <0x11006000 0x1000>;
		};

		simswitch@0 {
			compatible = "mediatek,sim_switch";
			linux,phandle = <0x5c>;
			phandle = <0x5c>;
			pinctrl-0 = <0x22>;
			pinctrl-1 = <0x23>;
			pinctrl-2 = <0x24>;
			pinctrl-3 = <0x25>;
			pinctrl-4 = <0x26>;
			pinctrl-names = "default", "hot_plug_mode1", "hot_plug_mode2", "two_sims_bound_to_md1", "sim1_md3_sim2_md1";
		};

		smi_common@14017000 {
			compatible = "mediatek,smi_common";
			mmsys_config = <0x27>;
			nr_larbs = <0x3>;
			reg = <0x14017000 0x1000 0x14016000 0x1000 0x16010000 0x1000 0x15001000 0x1000>;
		};

		smi_larb0@14016000 {
			cell-index = <0x0>;
			compatible = "mediatek,smi_larb0", "mediatek,smi_larb";
			interrupts = <0x0 0xb0 0x8>;
			reg = <0x14016000 0x1000>;
		};

		smi_larb1@16010000 {
			cell-index = <0x1>;
			compatible = "mediatek,smi_larb1", "mediatek,smi_larb";
			interrupts = <0x0 0xb1 0x8>;
			reg = <0x16010000 0x1000>;
		};

		smi_larb2@15001000 {
			cell-index = <0x2>;
			compatible = "mediatek,smi_larb2", "mediatek,smi_larb";
			interrupts = <0x0 0xb2 0x8>;
			reg = <0x15001000 0x1000>;
		};

		sys_cirq@10204000 {
			compatible = "mediatek,sys_cirq";
			interrupts = <0x0 0xe7 0x8>;
			linux,phandle = <0x5e>;
			mediatek,cirq_num = <0x9f>;
			mediatek,spi_start_offset = <0x48>;
			phandle = <0x5e>;
			reg = <0x10204000 0x1000>;
		};

		syscfg_pctl_a@0x10211000 {
			compatible = "mediatek,mt6735-pctl-a-syscfg", "syscon";
			linux,phandle = <0x28>;
			phandle = <0x28>;
			reg = <0x10211000 0x1000>;
		};

		touch@ {
			compatible = "mediatek,touch";
			linux,phandle = <0x67>;
			phandle = <0x67>;
			vtouch-supply = <0x29>;
		};

		usb20@11200000 {
			cell-index = <0x0>;
			compatible = "mediatek,mt6735-usb20";
			dma = <0x1>;
			dma_channels = <0x8>;
			drvvbus_gpio = <0x53 0x2>;
			dyn_fifo = <0x1>;
			interrupts = <0x0 0x48 0x8>;
			linux,phandle = <0x6a>;
			mode = <0x2>;
			multipoint = <0x1>;
			num_eps = <0x10>;
			phandle = <0x6a>;
			reg = <0x11200000 0x10000 0x11210000 0x10000>;
			soft_con = <0x1>;
		};

		usb2jtag@10000000 {
			compatible = "mediatek,usb2jtag_v1";
			linux,phandle = <0x56>;
			phandle = <0x56>;
			reg = <0x10000000 0x1000 0x11210000 0x1000>;
		};

		usbiddig {
			compatible = "mediatek,usb_iddig_eint";
			linux,phandle = <0x6b>;
			phandle = <0x6b>;
		};

		wifi@180F0000 {
			compatible = "mediatek,wifi";
			interrupts = <0x0 0xe2 0x8>;
			reg = <0x180f0000 0x5c>;
		};
	};

	chosen {
		bootargs = "console=tty0 console=ttyMT3,921600n1 vmalloc=400M androidboot.hardware=mt6735 slub_max_order=0 slub_debug=OFZPU swiotlb=noforce firmware_class.path=/vendor/firmware loop.max_part=7";
		linux,phandle = <0x32>;
		phandle = <0x32>;
	};

	chr_stat {
		compatible = "mediatek, chr_stat-eint";
		linux,phandle = <0x80>;
		phandle = <0x80>;
	};

	cpus {
		#address-cells = <0x1>;
		#size-cells = <0x0>;
		linux,phandle = <0x36>;
		phandle = <0x36>;

		cpu@000 {
			clock-frequency = <0x3b9aca00>;
			compatible = "arm,cortex-a53";
			cpu-release-addr = <0x0 0x40000200>;
			device_type = "cpu";
			enable-method = "spin-table";
			linux,phandle = <0x2>;
			phandle = <0x2>;
			reg = <0x0>;
		};

		cpu@001 {
			clock-frequency = <0x3b9aca00>;
			compatible = "arm,cortex-a53";
			cpu-release-addr = <0x0 0x40000200>;
			device_type = "cpu";
			enable-method = "spin-table";
			linux,phandle = <0x3>;
			phandle = <0x3>;
			reg = <0x1>;
		};

		cpu@002 {
			clock-frequency = <0x3b9aca00>;
			compatible = "arm,cortex-a53";
			cpu-release-addr = <0x0 0x40000200>;
			device_type = "cpu";
			enable-method = "spin-table";
			linux,phandle = <0x4>;
			phandle = <0x4>;
			reg = <0x2>;
		};

		cpu@003 {
			clock-frequency = <0x3b9aca00>;
			compatible = "arm,cortex-a53";
			cpu-release-addr = <0x0 0x40000200>;
			device_type = "cpu";
			enable-method = "spin-table";
			linux,phandle = <0x5>;
			phandle = <0x5>;
			reg = <0x3>;
		};
	};

	cust_accel@0 {
		compatible = "mediatek,mir3da";
		linux,phandle = <0x83>;
		phandle = <0x83>;
	};

	cust_accel@1 {
		compatible = "mediatek,mxc622x_auto";
		linux,phandle = <0x84>;
		phandle = <0x84>;
	};

	cust_accel@2 {
		compatible = "mediatek,mc3xxx_auto";
		linux,phandle = <0x85>;
		phandle = <0x85>;
	};

	cust_accel@3 {
		compatible = "mediatek,bma250_auto";
		linux,phandle = <0x86>;
		phandle = <0x86>;
	};

	cust_accel@4 {
		compatible = "mediatek,mxc400x";
		linux,phandle = <0x87>;
		phandle = <0x87>;
	};

	cust_accel@5 {
		compatible = "mediatek,sc7a20";
		linux,phandle = <0x88>;
		phandle = <0x88>;
	};

	cust_accel@6 {
		compatible = "mediatek,bmi160";
		linux,phandle = <0x89>;
		phandle = <0x89>;
	};

	cust_accel@9 {
		compatible = "mediatek,teksun_acc";
		direction = <0x3>;
		firlen = <0x0>;
		i2c_addr = <0x18 0x0 0x0 0x0>;
		i2c_num = <0x4>;
		is_batch_supported = <0x0>;
		power_id = <0xffff>;
		power_vol = <0x0>;
	};

	cust_alsps@0 {
		compatible = "mediatek,ltr578";
		linux,phandle = <0x8a>;
		phandle = <0x8a>;
	};

	cust_alsps@1 {
		compatible = "mediatek,stk3x1x_auto";
		linux,phandle = <0x8b>;
		phandle = <0x8b>;
	};

	cust_alsps@2 {
		compatible = "mediatek,EPL259x";
		linux,phandle = <0x8c>;
		phandle = <0x8c>;
	};

	cust_alsps@3 {
		compatible = "mediatek,em3071x";
		linux,phandle = <0x8d>;
		phandle = <0x8d>;
	};

	cust_alsps@4 {
		compatible = "mediatek,stk3x1x";
		linux,phandle = <0x8e>;
		phandle = <0x8e>;
	};

	cust_alsps@5 {
		compatible = "mediatek,stk3332_auto";
		linux,phandle = <0x8f>;
		phandle = <0x8f>;
	};

	cust_alsps@6 {
		compatible = "mediatek,stk3x3x_auto";
		linux,phandle = <0x90>;
		phandle = <0x90>;
	};

	cust_alsps@9 {
		als_level = <0x5 0x9 0x24 0x3b 0x52 0x84 0xcd 0x111 0x1f4 0x34d 0x470 0x609 0x93c 0x122f 0x1b46>;
		als_value = <0xa 0x14 0x23 0x2d 0x46 0x73 0xb4 0xf0 0x15e 0x212 0x352 0x6a4 0xa28 0x1400 0x1e00 0x2800>;
		alsctrl_val = <0x39>;
		compatible = "mediatek,teksun_alsps";
		i2c_addr = <0x48 0x0 0x0 0x0>;
		i2c_num = <0x3>;
		is_batch_supported_als = <0x0>;
		is_batch_supported_ps = <0x0>;
		ledctrl_val = <0xff>;
		linux,phandle = <0x95>;
		phandle = <0x95>;
		polling_mode_als = <0x1>;
		polling_mode_ps = <0x0>;
		power_id = <0xffff>;
		power_vol = <0x0>;
		ps_threshold_high = <0x96>;
		ps_threshold_low = <0x64>;
		psctrl_val = <0x31>;
		state_val = <0x0>;
		wait_val = <0x7>;
	};

	cust_auxiliarycamera {
		compatible = "mediatek,auxiliarycamera";
		linux,phandle = <0x81>;
		phandle = <0x81>;

		auxiliarycamera_parameter {
			cam3_1_bv_value = "gc0310,68,2";
			cam3_2_bv_value = "null";
			cam3_3_bv_value = "null";
			compatible = "mediatek,auxiliarycamera_parameter";
			cumulative_cyles = <0x2>;
			diff_percent = <0x1e>;
			linux,phandle = <0x82>;
			main1_bv_value = "gc8024mipiraw,48,-50";
			main2_bv_value = "null";
			main3_bv_value = "null";
			main4_bv_value = "null";
			main5_bv_value = "null";
			phandle = <0x82>;
		};
	};

	cust_gyro@0 {
		compatible = "mediatek,bmg250";
		linux,phandle = <0x92>;
		phandle = <0x92>;
	};

	cust_gyro@1 {
		compatible = "mediatek,bmi160_gyro";
		linux,phandle = <0x93>;
		phandle = <0x93>;
	};

	cust_mag@0 {
		compatible = "mediatek,mmc5603x";
		linux,phandle = <0x91>;
		phandle = <0x91>;
	};

	finger {
		compatible = "mediatek,teksun-finger";
		linux,phandle = <0x79>;
		phandle = <0x79>;
		vgp1finger-supply = <0x29>;
	};

	flashlights_subflashlight@0 {
		compatible = "mediatek,flashlights_subflashlight_gpio";
		linux,phandle = <0x7b>;
		phandle = <0x7b>;
	};

	gsensor@0 {
		compatible = "mediatek,gsensor";
		linux,phandle = <0x74>;
		phandle = <0x74>;
	};

	gyroscope@0 {
		compatible = "mediatek,gyroscope";
		linux,phandle = <0x76>;
		phandle = <0x76>;
	};

	hall_1 {
		compatible = "mediatek,hall_1";
		linux,phandle = <0x7e>;
		phandle = <0x7e>;
	};

	hwmsensor@0 {
		compatible = "mediatek,hwmsensor";
	};

	interrupt-controller@10220000 {
		#address-cells = <0x0>;
		#interrupt-cells = <0x3>;
		compatible = "mediatek,mt6735-gic";
		interrupt-controller;
		linux,phandle = <0x1>;
		mediatek,wdt_irq = <0xa0>;
		phandle = <0x1>;
		reg = <0x0 0x10221000 0x0 0x1000 0x0 0x10222000 0x0 0x1000 0x0 0x10200620 0x0 0x1000>;

		gic-cpuif@0 {
			compatible = "arm,gic-cpuif";
			cpu = <0x2>;
			cpuif-id = <0x0>;
		};

		gic-cpuif@1 {
			compatible = "arm,gic-cpuif";
			cpu = <0x3>;
			cpuif-id = <0x1>;
		};

		gic-cpuif@2 {
			compatible = "arm,gic-cpuif";
			cpu = <0x4>;
			cpuif-id = <0x2>;
		};

		gic-cpuif@3 {
			compatible = "arm,gic-cpuif";
			cpu = <0x5>;
			cpuif-id = <0x3>;
		};
	};

	lcm {
		compatible = "mediatek,lcm";
		linux,phandle = <0x73>;
		phandle = <0x73>;
	};

	lcm_mode {
		compatible = "mediatek,lcm_mode";
		linux,phandle = <0x7c>;
		phandle = <0x7c>;
		pinctrl-0 = <0x2e>;
		pinctrl-1 = <0x2f>;
		pinctrl-2 = <0x30>;
		pinctrl-3 = <0x31>;
		pinctrl-names = "default", "lcm_rst", "lcm_rst_gpio_high", "lcm_rst_gpio_low";
	};

	m_acc_pl@0 {
		compatible = "mediatek,m_acc_pl";
	};

	m_alsps_pl@0 {
		compatible = "mediatek,m_alsps_pl";
	};

	m_baro_pl@0 {
		compatible = "mediatek,m_baro_pl";
	};

	m_batch_pl@0 {
		compatible = "mediatek,m_batch_pl";
	};

	m_gyro_pl@0 {
		compatible = "mediatek,m_gyro_pl";
	};

	m_mag_pl@0 {
		compatible = "mediatek,m_mag_pl";
	};

	memory {
		device_type = "memory";
		reg = <0x0 0x40000000 0x0 0x40000000>;
	};

	mhall {
		compatible = "mediatek,mhall";
		linux,phandle = <0x7d>;
		phandle = <0x7d>;
	};

	msdc1_ins@0 {
		compatible = "mediatek,mt6735-sdcard-ins";
		linux,phandle = <0x35>;
		phandle = <0x35>;
	};

	msdc@11230000 {
		compatible = "mediatek,msdc";
		interrupts = <0x0 0x4f 0x8>;
		linux,phandle = <0x33>;
		phandle = <0x33>;
		reg = <0x0 0x11230000 0x0 0x10000>;
	};

	msdc@11240000 {
		compatible = "mediatek,msdc";
		interrupts = <0x0 0x50 0x8>;
		linux,phandle = <0x34>;
		phandle = <0x34>;
		reg = <0x0 0x11240000 0x0 0x10000>;
	};

	msensor@0 {
		compatible = "mediatek,msensor";
	};

	odm {
		compatible = "simple-bus";
		linux,phandle = <0x78>;
		phandle = <0x78>;
	};

	orientation@0 {
		compatible = "mediatek,orientation";
	};

	otg_iddig {
		compatible = "mediatek, otg_iddig-eint";
		linux,phandle = <0x7f>;
		phandle = <0x7f>;
	};

	psci {
		affinity_info = <0x84000004>;
		compatible = "arm,psci";
		cpu_off = <0x84000002>;
		cpu_on = <0x84000003>;
		cpu_suspend = <0x84000001>;
		method = "smc";
	};

	reserved-memory {
		#address-cells = <0x2>;
		#size-cells = <0x2>;
		linux,phandle = <0x37>;
		phandle = <0x37>;
		ranges;

		atf-reserved-memory@43000000 {
			compatible = "mediatek,mt6735-atf-reserved-memory", "mediatek,mt6735m-atf-reserved-memory", "mediatek,mt6753-atf-reserved-memory";
			no-map;
			reg = <0x0 0x43000000 0x0 0x30000>;
		};

		consys-reserve-memory {
			alignment = <0x0 0x200000>;
			compatible = "mediatek,consys-reserve-memory";
			no-map;
			size = <0x0 0x100000>;
		};

		reserve-memory-ccci_md1 {
			alignment = <0x0 0x2000000>;
			alloc-ranges = <0x0 0x40000000 0x0 0xc0000000>;
			compatible = "mediatek,reserve-memory-ccci_md1";
			no-map;
			size = <0x0 0x3810000>;
		};

		spm-reserve-memory {
			alignment = <0x0 0x10000>;
			alloc-ranges = <0x0 0x40000000 0x0 0x60000000>;
			compatible = "mediatek,spm-reserve-memory";
			no-map;
			size = <0x0 0x10000>;
		};
	};

	rf_clock_buffer {
		compatible = "mediatek,rf_clock_buffer";
		linux,phandle = <0x77>;
		mediatek,clkbuf-config = <0x2 0x2 0x2 0x2>;
		mediatek,clkbuf-quantity = <0x4>;
		phandle = <0x77>;
	};

	soc {
		#address-cells = <0x1>;
		#size-cells = <0x1>;
		compatible = "simple-bus";
		ranges = <0x0 0x0 0x0 0xffffffff>;

		als {
			compatible = "mediatek, als-eint";
			linux,phandle = <0x4f>;
			phandle = <0x4f>;
		};

		apuart0@11002000 {
			cell-index = <0x0>;
			compatible = "mediatek,mt6735-uart";
			interrupts = <0x0 0x5b 0x8 0x0 0x67 0x8 0x0 0x68 0x8>;
			linux,phandle = <0x48>;
			phandle = <0x48>;
			reg = <0x11002000 0x1000 0x11000380 0x1000 0x11000400 0x80>;
			skip_pinmux_clk = <0x1>;
		};

		apuart1@11003000 {
			cell-index = <0x1>;
			compatible = "mediatek,mt6735-uart";
			interrupts = <0x0 0x5c 0x8 0x0 0x69 0x8 0x0 0x6a 0x8>;
			linux,phandle = <0x49>;
			phandle = <0x49>;
			reg = <0x11003000 0x1000 0x11000480 0x80 0x11000500 0x80>;
			skip_pinmux_clk = <0x1>;
		};

		apuart2@11004000 {
			cell-index = <0x2>;
			compatible = "mediatek,mt6735-uart";
			interrupts = <0x0 0x5d 0x8 0x0 0x6b 0x8 0x0 0x6c 0x8>;
			linux,phandle = <0x4a>;
			phandle = <0x4a>;
			reg = <0x11004000 0x1000 0x11000580 0x80 0x11000600 0x80>;
			skip_pinmux_clk = <0x1>;
		};

		apuart3@11005000 {
			cell-index = <0x3>;
			compatible = "mediatek,mt6735-uart";
			interrupts = <0x0 0x5e 0x8 0x0 0x6d 0x8 0x0 0x6e 0x8>;
			linux,phandle = <0x4b>;
			phandle = <0x4b>;
			reg = <0x11005000 0x1000 0x11000680 0x80 0x11000700 0x80>;
			skip_pinmux_clk = <0x1>;
		};

		apxgpt@10004000 {
			clock-frequency = <0xc65d40>;
			compatible = "mediatek,APXGPT";
			interrupts = <0x0 0x98 0x8>;
			linux,phandle = <0x39>;
			phandle = <0x39>;
			reg = <0x10004000 0x1000>;
		};

		consys@18070000 {
			compatible = "mediatek,mt6735m-consys", "mediatek,mt6735-consys";
			interrupts = <0x0 0xe3 0x8 0x0 0xe1 0x8>;
			linux,phandle = <0x4d>;
			phandle = <0x4d>;
			reg = <0x18070000 0x200 0x10212000 0x100 0x10000000 0x2000 0x10006000 0x1000>;
			vcn18-supply = <0x18>;
			vcn28-supply = <0x19>;
			vcn33_bt-supply = <0x1a>;
			vcn33_wifi-supply = <0x1b>;
		};

		cpuxgpt@10200000 {
			compatible = "mediatek,mt6735-cpuxgpt";
			interrupts = <0x0 0x40 0x4 0x0 0x41 0x4 0x0 0x42 0x4 0x0 0x43 0x4 0x0 0x44 0x4 0x0 0x45 0x4 0x0 0x46 0x4 0x0 0x47 0x4>;
			linux,phandle = <0x38>;
			phandle = <0x38>;
			reg = <0x10200000 0x1000>;
		};

		ddrphy@10213000 {
			compatible = "mediatek,mt6735-ddrphy";
			linux,phandle = <0x45>;
			phandle = <0x45>;
			reg = <0x10213000 0x1000>;
		};

		dramc@10214000 {
			clock-names = "infra-cqdma";
			compatible = "mediatek,mt6735-dramc";
			linux,phandle = <0x46>;
			phandle = <0x46>;
			reg = <0x10214000 0x1000>;
		};

		dramc_nao@1020e000 {
			compatible = "mediatek,mt6735-dramc_nao";
			linux,phandle = <0x44>;
			phandle = <0x44>;
			reg = <0x1020e000 0x1000>;
		};

		dsi_te {
			compatible = "mediatek, DSI_TE_1-eint";
			linux,phandle = <0x53>;
			phandle = <0x53>;
			status = "disabled";
		};

		ext_buck_oc {
			compatible = "mediatek, ext_buck_oc-eint";
			linux,phandle = <0x51>;
			phandle = <0x51>;
			status = "disabled";
		};

		gpio {
			compatible = "mediatek,gpio_usage_mapping";
			linux,phandle = <0x42>;
			phandle = <0x42>;
		};

		gpio@10211000 {
			compatible = "mediatek,gpio";
			linux,phandle = <0x43>;
			phandle = <0x43>;
			reg = <0x10211000 0x1000>;
		};

		gse_1 {
			compatible = "mediatek, gse_1-eint";
			linux,phandle = <0x50>;
			phandle = <0x50>;
			status = "disabled";
		};

		hacc@10008000 {
			compatible = "mediatek,hacc";
			interrupts = <0x0 0xae 0x8>;
			linux,phandle = <0x4e>;
			phandle = <0x4e>;
			reg = <0x10008000 0x1000>;
		};

		hwrng {
			compatible = "mediatek,mt67xx-rng";
			linux,phandle = <0x54>;
			phandle = <0x54>;
		};

		irtx@11011000 {
			compatible = "mediatek,irtx";
			interrupts = <0x0 0x7c 0x4>;
			linux,phandle = <0x47>;
			phandle = <0x47>;
			pwm_ch = <0x0>;
			reg = <0x11011000 0x1000>;
		};

		mcu_biu@10300000 {
			compatible = "mediatek,mt6735-mcu_biu";
			linux,phandle = <0x41>;
			phandle = <0x41>;
			reg = <0x10300000 0x8000>;
		};

		mt_pmic_regulator {
			compatible = "mediatek,mt_pmic";

			buck_regulators {
				compatible = "mediatek,mt_pmic_buck_regulators";

				buck_vcore1 {
					linux,phandle = <0x3c>;
					phandle = <0x3c>;
					regulator-always-on;
					regulator-boot-on;
					regulator-enable-ramp-delay = <0xb4>;
					regulator-max-microvolt = <0x154456>;
					regulator-min-microvolt = <0x927c0>;
					regulator-name = "vcore1";
					regulator-ramp-delay = <0x186a>;
				};

				buck_vlte {
					linux,phandle = <0x3e>;
					phandle = <0x3e>;
					regulator-always-on;
					regulator-boot-on;
					regulator-enable-ramp-delay = <0xb4>;
					regulator-max-microvolt = <0x154456>;
					regulator-min-microvolt = <0x927c0>;
					regulator-name = "vlte";
					regulator-ramp-delay = <0x186a>;
				};

				buck_vpa {
					linux,phandle = <0x3a>;
					phandle = <0x3a>;
					regulator-enable-ramp-delay = <0xb4>;
					regulator-max-microvolt = <0x37b1d0>;
					regulator-min-microvolt = <0x7a120>;
					regulator-name = "vpa";
					regulator-ramp-delay = <0xc350>;
				};

				buck_vproc {
					linux,phandle = <0x3b>;
					phandle = <0x3b>;
					regulator-always-on;
					regulator-boot-on;
					regulator-enable-ramp-delay = <0xb4>;
					regulator-max-microvolt = <0x154456>;
					regulator-min-microvolt = <0x927c0>;
					regulator-name = "vproc";
					regulator-ramp-delay = <0x186a>;
				};

				buck_vsys22 {
					linux,phandle = <0x3d>;
					phandle = <0x3d>;
					regulator-always-on;
					regulator-boot-on;
					regulator-enable-ramp-delay = <0xb4>;
					regulator-max-microvolt = <0x1e6c16>;
					regulator-min-microvolt = <0x124f80>;
					regulator-name = "vsys22";
					regulator-ramp-delay = <0x186a>;
				};
			};

			ldo_regulators {
				compatible = "mediatek,mt_pmic_ldo_regulators";

				ldo_vaud28 {
					linux,phandle = <0x9>;
					phandle = <0x9>;
					regulator-boot-on;
					regulator-enable-ramp-delay = <0x108>;
					regulator-max-microvolt = <0x2ab980>;
					regulator-min-microvolt = <0x2ab980>;
					regulator-name = "vaud28";
				};

				ldo_vaux18 {
					linux,phandle = <0x6>;
					phandle = <0x6>;
					regulator-boot-on;
					regulator-enable-ramp-delay = <0x108>;
					regulator-max-microvolt = <0x1b7740>;
					regulator-min-microvolt = <0x1b7740>;
					regulator-name = "vaux18";
				};

				ldo_vcama {
					linux,phandle = <0x2a>;
					phandle = <0x2a>;
					regulator-enable-ramp-delay = <0x108>;
					regulator-max-microvolt = <0x2ab980>;
					regulator-min-microvolt = <0x16e360>;
					regulator-name = "vcama";
				};

				ldo_vcamaf {
					linux,phandle = <0x2c>;
					phandle = <0x2c>;
					regulator-enable-ramp-delay = <0x108>;
					regulator-max-microvolt = <0x325aa0>;
					regulator-min-microvolt = <0x124f80>;
					regulator-name = "vcamaf";
				};

				ldo_vcamd {
					linux,phandle = <0x2b>;
					phandle = <0x2b>;
					regulator-enable-ramp-delay = <0x108>;
					regulator-max-microvolt = <0x16e360>;
					regulator-min-microvolt = <0xdbba0>;
					regulator-name = "vcamd";
				};

				ldo_vcamio {
					linux,phandle = <0x2d>;
					phandle = <0x2d>;
					regulator-enable-ramp-delay = <0xdc>;
					regulator-max-microvolt = <0x1b7740>;
					regulator-min-microvolt = <0x124f80>;
					regulator-name = "vcamio";
				};

				ldo_vcn18 {
					linux,phandle = <0x18>;
					phandle = <0x18>;
					regulator-enable-ramp-delay = <0x2c>;
					regulator-max-microvolt = <0x1b7740>;
					regulator-min-microvolt = <0x1b7740>;
					regulator-name = "vcn18";
				};

				ldo_vcn28 {
					linux,phandle = <0x19>;
					phandle = <0x19>;
					regulator-enable-ramp-delay = <0x108>;
					regulator-max-microvolt = <0x2ab980>;
					regulator-min-microvolt = <0x2ab980>;
					regulator-name = "vcn28";
				};

				ldo_vcn33_bt {
					linux,phandle = <0x1a>;
					phandle = <0x1a>;
					regulator-enable-ramp-delay = <0x108>;
					regulator-max-microvolt = <0x36ee80>;
					regulator-min-microvolt = <0x325aa0>;
					regulator-name = "vcn33_bt";
				};

				ldo_vcn33_wifi {
					linux,phandle = <0x1b>;
					phandle = <0x1b>;
					regulator-enable-ramp-delay = <0x108>;
					regulator-max-microvolt = <0x36ee80>;
					regulator-min-microvolt = <0x325aa0>;
					regulator-name = "vcn33_wifi";
				};

				ldo_vefuse {
					linux,phandle = <0xa>;
					phandle = <0xa>;
					regulator-enable-ramp-delay = <0x108>;
					regulator-max-microvolt = <0x2191c0>;
					regulator-min-microvolt = <0x1b7740>;
					regulator-name = "vefuse";
				};

				ldo_vemc_3v3 {
					linux,phandle = <0xd>;
					phandle = <0xd>;
					regulator-boot-on;
					regulator-enable-ramp-delay = <0x108>;
					regulator-max-microvolt = <0x325aa0>;
					regulator-min-microvolt = <0x1b7740>;
					regulator-name = "vemc_3v3";
				};

				ldo_vgp1 {
					linux,phandle = <0x29>;
					phandle = <0x29>;
					regulator-enable-ramp-delay = <0x108>;
					regulator-max-microvolt = <0x325aa0>;
					regulator-min-microvolt = <0x124f80>;
					regulator-name = "vgp1";
				};

				ldo_vibr {
					linux,phandle = <0x12>;
					phandle = <0x12>;
					regulator-enable-ramp-delay = <0x2c>;
					regulator-max-microvolt = <0x325aa0>;
					regulator-min-microvolt = <0x124f80>;
					regulator-name = "vibr";
				};

				ldo_vio18 {
					linux,phandle = <0x15>;
					phandle = <0x15>;
					regulator-boot-on;
					regulator-enable-ramp-delay = <0x108>;
					regulator-max-microvolt = <0x1b7740>;
					regulator-min-microvolt = <0x1b7740>;
					regulator-name = "vio18";
				};

				ldo_vio28 {
					linux,phandle = <0x11>;
					phandle = <0x11>;
					regulator-boot-on;
					regulator-enable-ramp-delay = <0x108>;
					regulator-max-microvolt = <0x2ab980>;
					regulator-min-microvolt = <0x2ab980>;
					regulator-name = "vio28";
				};

				ldo_vm {
					linux,phandle = <0x17>;
					phandle = <0x17>;
					regulator-boot-on;
					regulator-enable-ramp-delay = <0x108>;
					regulator-max-microvolt = <0x177fa0>;
					regulator-min-microvolt = <0x12ebc0>;
					regulator-name = "vm";
				};

				ldo_vmc {
					linux,phandle = <0x10>;
					phandle = <0x10>;
					regulator-enable-ramp-delay = <0x2c>;
					regulator-max-microvolt = <0x325aa0>;
					regulator-min-microvolt = <0x1b7740>;
					regulator-name = "vmc";
				};

				ldo_vmch {
					linux,phandle = <0xe>;
					phandle = <0xe>;
					regulator-enable-ramp-delay = <0x2c>;
					regulator-max-microvolt = <0x325aa0>;
					regulator-min-microvolt = <0x2c4020>;
					regulator-name = "vmch";
				};

				ldo_vrf18_0 {
					linux,phandle = <0x13>;
					phandle = <0x13>;
					regulator-enable-ramp-delay = <0xdc>;
					regulator-max-microvolt = <0x1bd8e8>;
					regulator-min-microvolt = <0x1bd8e8>;
					regulator-name = "vrf18_0";
				};

				ldo_vrf18_1 {
					linux,phandle = <0x14>;
					phandle = <0x14>;
					regulator-enable-ramp-delay = <0xdc>;
					regulator-max-microvolt = <0x1bd8e8>;
					regulator-min-microvolt = <0x124f80>;
					regulator-name = "vrf18_1";
				};

				ldo_vsim1 {
					linux,phandle = <0xb>;
					phandle = <0xb>;
					regulator-enable-ramp-delay = <0x108>;
					regulator-max-microvolt = <0x200b20>;
					regulator-min-microvolt = <0x19f0a0>;
					regulator-name = "vsim1";
				};

				ldo_vsim2 {
					linux,phandle = <0xc>;
					phandle = <0xc>;
					regulator-enable-ramp-delay = <0x108>;
					regulator-max-microvolt = <0x200b20>;
					regulator-min-microvolt = <0x19f0a0>;
					regulator-name = "vsim2";
				};

				ldo_vsram {
					linux,phandle = <0x16>;
					phandle = <0x16>;
					regulator-boot-on;
					regulator-enable-ramp-delay = <0xdc>;
					regulator-max-microvolt = <0x16caf6>;
					regulator-min-microvolt = <0xaae60>;
					regulator-name = "vsram";
					regulator-ramp-delay = <0x186a>;
				};

				ldo_vtcxo_0 {
					linux,phandle = <0x7>;
					phandle = <0x7>;
					regulator-boot-on;
					regulator-enable-ramp-delay = <0x6e>;
					regulator-max-microvolt = <0x2ab980>;
					regulator-min-microvolt = <0x2ab980>;
					regulator-name = "vtcxo_0";
				};

				ldo_vtcxo_1 {
					linux,phandle = <0x8>;
					phandle = <0x8>;
					regulator-enable-ramp-delay = <0x6e>;
					regulator-max-microvolt = <0x2ab980>;
					regulator-min-microvolt = <0x2ab980>;
					regulator-name = "vtcxo_1";
				};

				ldo_vtref {
					linux,phandle = <0xf>;
					phandle = <0xf>;
					regulator-enable-ramp-delay = <0xf0>;
					regulator-max-microvolt = <0x1b7740>;
					regulator-min-microvolt = <0x1b7740>;
					regulator-name = "vtref";
				};

				ldo_vusb33 {
					linux,phandle = <0x3f>;
					phandle = <0x3f>;
					regulator-boot-on;
					regulator-enable-ramp-delay = <0x108>;
					regulator-max-microvolt = <0x325aa0>;
					regulator-min-microvolt = <0x325aa0>;
					regulator-name = "vusb33";
				};
			};

			regulators_supply {
				compatible = "mediatek,mt_pmic_regulator_supply";
				vaud28-supply = <0x9>;
				vaux18-supply = <0x6>;
				vefuse-supply = <0xa>;
				vemc_3v3-supply = <0xd>;
				vibr-supply = <0x12>;
				vio18-supply = <0x15>;
				vio28-supply = <0x11>;
				vm-supply = <0x17>;
				vmc-supply = <0x10>;
				vmch-supply = <0xe>;
				vrf18_0-supply = <0x13>;
				vrf18_1-supply = <0x14>;
				vsim1-supply = <0xb>;
				vsim2-supply = <0xc>;
				vsram-supply = <0x16>;
				vtcxo_0-supply = <0x7>;
				vtcxo_1-supply = <0x8>;
				vtref-supply = <0xf>;
			};
		};

		pmu {
			compatible = "arm,cortex-a7-pmu";
			interrupt-affinity = <0x2 0x3 0x4 0x5>;
			interrupts = <0x0 0x8 0x8 0x0 0x9 0x8 0x0 0xa 0x8 0x0 0xb 0x8>;
		};

		spi@1100a000 {
			cell-index = <0x0>;
			compatible = "mediatek,mt6735m-spi";
			interrupts = <0x0 0x76 0x8>;
			linux,phandle = <0x4c>;
			phandle = <0x4c>;
			reg = <0x1100a000 0x1000>;
			spi-padmacro = <0x1>;
		};

		swtp {
			compatible = "mediatek, swtp-eint";
			linux,phandle = <0x52>;
			phandle = <0x52>;
		};

		timer {
			clock-frequency = <0xc65d40>;
			compatible = "arm,armv8-timer";
			interrupts = <0x1 0xd 0x8 0x1 0xe 0x8 0x1 0xb 0x8 0x1 0xa 0x8>;
		};

		toprgu@10212000 {
			compatible = "mediatek,mt6735-rgu";
			interrupts = <0x0 0x80 0x2>;
			linux,phandle = <0x40>;
			phandle = <0x40>;
			reg = <0x10212000 0x1000>;
		};
	};

	strobe_main {
		compatible = "mediatek,strobe_main";
		linux,phandle = <0x7a>;
		phandle = <0x7a>;
	};

	switch_charging {
		compatible = "mediatek,teksun_charging";
		linux,phandle = <0x96>;
		phandle = <0x96>;
	};

	temp@0 {
		compatible = "mediatek,temprerature";
		linux,phandle = <0x94>;
		phandle = <0x94>;
	};

	tkcore {
		compatible = "trustkernel,tkcore";
		interrupts = <0x0 0xf8 0x1>;
	};

	trusty {
		#address-cells = <0x2>;
		#size-cells = <0x2>;
		compatible = "android,trusty-smc-v1";
		ranges;

		irq {
			compatible = "android,trusty-irq-v1";
			ppi-interrupt-parent = <0x1>;
		};

		log {
			compatible = "android,trusty-log-v1";
		};

		mtee {
			compatible = "mediatek,trusty-mtee-v1";
		};

		virtio {
			compatible = "android,trusty-virtio-v1";
		};
	};

	utos {
		compatible = "microtrust,utos";
		interrupts = <0x0 0xfc 0x1 0x0 0xfd 0x1>;
	};

	utos_tester {
		compatible = "microtrust,tester-v1";
	};
};
